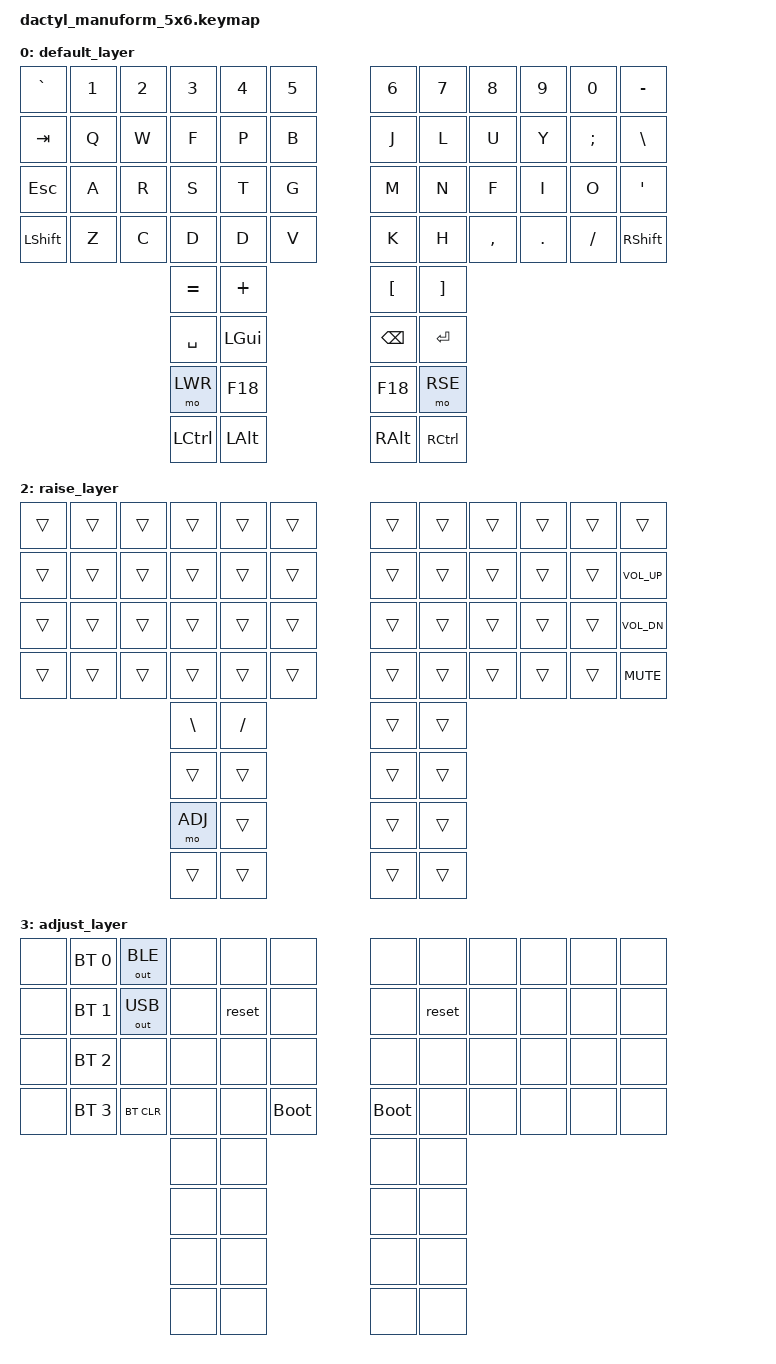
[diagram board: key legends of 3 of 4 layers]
#include <behaviors.dtsi>
#include <dt-bindings/zmk/keys.h>
#include <dt-bindings/zmk/bt.h>
#include <dt-bindings/zmk/outputs.h>

#define DEFAULT 0
#define LWR 1
#define RSE 2
#define ADJ 3

/ {

    keymap {
        compatible = "zmk,keymap";

        default_layer {
            bindings = <
                &kp GRAVE  &kp N1  &kp N2  &kp N3  &kp N4  &kp N5              &kp N6  &kp N7  &kp N8     &kp N9  &kp N0    &kp MINUS
                &kp TAB    &kp Q   &kp W   &kp F   &kp P   &kp B               &kp J   &kp L   &kp U      &kp Y   &kp SEMI  &kp BSLH
                &kp ESC    &kp A   &kp R   &kp S   &kp T   &kp G               &kp M   &kp N   &kp F      &kp I   &kp O     &kp SQT
                &kp LSHIFT &kp Z   &kp C   &kp D   &kp D   &kp V               &kp K   &kp H   &kp COMMA  &kp DOT &kp FSLH  &kp RSHIFT
                                            &kp EQUAL  &kp PLUS                &kp LBKT  &kp RBKT
                                            &kp SPACE  &kp LGUI                &kp BSPC  &kp RET
                                            &mo LWR    &kp F18                 &kp F18   &mo RSE
                                            &kp LCTRL  &kp LALT                &kp RALT  &kp RCTRL
            >;
        };

        lower_layer {
            bindings = <
                &kp F12 &kp F1 &kp F2   &kp F3   &kp F4    &kp F5                &kp F6 &kp F7   &kp F8     &kp F9    &kp F10     &kp F11
                &trans  &trans &trans   &kp UP   &trans    &trans                &trans &trans   &kp UP     &trans    &trans      &trans
                &trans  &trans &kp LEFT &kp DOWN &kp RIGHT &trans                &trans &kp LEFT &kp DOWN   &kp RIGHT &kp RSHIFT  &trans
                &trans  &kp ! &kp @   &kp #   &kp $    &kp %                     &kp ^ &kp &   &kp *     &kp (    &kp )      &kp _
                               &kp BSLH &kp FSLH                                                 &trans     &trans
                                                 &trans    &trans               &trans &trans
                                                 &trans    &trans               &trans &mo ADJ
                                                 &trans    &trans               &trans &trans
            >;
        };

        raise_layer {
            bindings = <
                &trans  &trans &trans &trans &trans   &trans                &trans &trans &trans &trans &trans &trans
                &trans  &trans &trans &trans &trans   &trans                &trans &trans &trans &trans &trans &kp K_VOL_UP
                &trans  &trans &trans &trans &trans   &trans                &trans &trans &trans &trans &trans &kp K_VOL_DN
                &trans  &trans &trans &trans &trans   &trans                &trans &trans &trans &trans &trans &kp K_MUTE
                                             &kp BSLH &kp FSLH              &trans &trans
                                             &trans   &trans                &trans &trans
                                             &mo ADJ  &trans                &trans &trans
                                             &trans   &trans                &trans &trans
            >;
        };

        adjust_layer {
            bindings = <
                &none &bt BT_SEL 0 &out OUT_BLE &none &none  &none            &none       &none  &none &none &none &none
                &none &bt BT_SEL 1 &out OUT_USB &none &reset &none            &none       &reset &none &none &none &none
                &none &bt BT_SEL 2 &none        &none &none  &none            &none       &none  &none &none &none &none
                &none &bt BT_SEL 3 &bt BT_CLR   &none &none  &bootloader      &bootloader &none  &none &none &none &none
                                   &none        &none                                            &none &none
                                                      &none &none             &none &none
                                                      &none &none             &none &none
                                                      &none &none             &none &none
            >;
        };
    };
};
